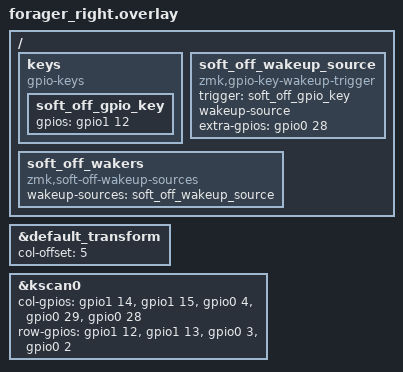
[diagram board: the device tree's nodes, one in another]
#include "forager.dtsi"

&default_transform {
    col-offset = <5>;
};

&kscan0 {
    col-gpios
    = <&gpio1 14 GPIO_ACTIVE_HIGH>
    , <&gpio1 15 GPIO_ACTIVE_HIGH>
    , <&gpio0 4 GPIO_ACTIVE_HIGH>
    , <&gpio0 29 GPIO_ACTIVE_HIGH>
    , <&gpio0 28 GPIO_ACTIVE_HIGH>
    ;

    row-gpios
    = <&gpio1 12 (GPIO_ACTIVE_HIGH | GPIO_PULL_DOWN)>
    , <&gpio1 13 (GPIO_ACTIVE_HIGH | GPIO_PULL_DOWN)>
    , <&gpio0 3 (GPIO_ACTIVE_HIGH | GPIO_PULL_DOWN)>
    , <&gpio0 2 (GPIO_ACTIVE_HIGH | GPIO_PULL_DOWN)>
    ;
 };

/ {
    keys {
        compatible = "gpio-keys";
        // top-right key: row 0 / col 4 (outermost)
        soft_off_gpio_key: soft_off_gpio_key {
            gpios = <&gpio1 12 (GPIO_ACTIVE_HIGH | GPIO_PULL_DOWN)>;
        };
    };

    soft_off_wakeup_source: soft_off_wakeup_source {
        compatible = "zmk,gpio-key-wakeup-trigger";
        trigger = <&soft_off_gpio_key>;
        wakeup-source;
        extra-gpios = <&gpio0 28 GPIO_ACTIVE_HIGH>;
    };

    soft_off_wakers: soft_off_wakers {
        compatible = "zmk,soft-off-wakeup-sources";
        wakeup-sources = <&soft_off_wakeup_source>;
    };
};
